VERSION ""

NS_ :

BS_:

BU_: TMS WPM2 WPM1 VCU EHPS_R EHPS_F BrakeSystemController SAS SIM Tester ADCU Cluster CM EBS

BO_ 2566832622 VDHR: 8 Vector__XXX
 SG_ HighResolutionTripDistance : 32|32@1+ (5,0) [0|21055406000] "m" Vector__XXX
 SG_ HghRsolutionTotalVehicleDistance : 0|32@1+ (5,0) [0|21055406000] "m" Vector__XXX

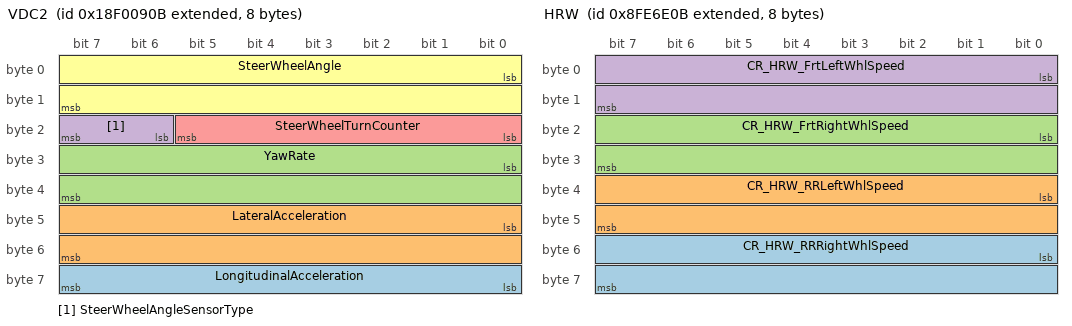
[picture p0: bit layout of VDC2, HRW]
BO_ 2565867787 VDC2: 8 Vector__XXX
 SG_ LongitudinalAcceleration : 56|8@1+ (0.1,-12.5) [-12.5|12.5] "m/s^2" Vector__XXX
 SG_ LateralAcceleration : 40|16@1+ (0.00048828125,-15.687) [-15.687|15.687] "m/s^2" Vector__XXX
 SG_ YawRate : 24|16@1+ (0.0001220703125,-3.92) [-3.92|3.92] "rad/s" Vector__XXX
 SG_ SteerWheelAngleSensorType : 22|2@1+ (1,0) [0|3] "" Vector__XXX
 SG_ SteerWheelTurnCounter : 16|6@1+ (1,-32) [-10|10] "turns" Vector__XXX
 SG_ SteerWheelAngle : 0|16@1+ (0.0009765625,-31.374) [-31.374|31.374] "rad" Vector__XXX

BO_ 2298375691 HRW: 8 BrakeSystemController
 SG_ CR_HRW_RRRightWhlSpeed : 48|16@1+ (0.00390625,0) [0|0] "KPH"  VCU
 SG_ CR_HRW_RRLeftWhlSpeed : 32|16@1+ (0.00390625,0) [0|0] "KPH"  VCU
 SG_ CR_HRW_FrtRightWhlSpeed : 16|16@1+ (0.00390625,0) [0|0] "KPH"  VCU
 SG_ CR_HRW_FrtLeftWhlSpeed : 0|16@1+ (0.00390625,0) [0|0] "KPH"  VCU

BA_DEF_ SG_  "GenSigILSupport" ENUM  "Yes","No";
BA_DEF_ SG_  "GenSigEVName" STRING ;
BA_DEF_ BO_  "GenMsgRequestable" INT 0 1;
BA_DEF_  "NMIdType" INT 0 1;
BA_DEF_ SG_  "SigType" ENUM  "Default","Range","RangeSigned","ASCII","Discrete","Control","ReferencePGN","DTC","StringDelimiter","StringLength","StringLengthControl";
BA_DEF_  "DatabaseVersion" STRING ;
BA_DEF_  "GenNWMApIndRingData" STRING ;
BA_DEF_ SG_  "Purpose" ENUM  "<t.b.d.>","Function","Diagnostic","Development","NM";
BA_DEF_ SG_  "Validity" ENUM  "B+","ACC","IGN";
BA_DEF_ SG_  "SignalCategory" HEX 10 15;
BA_DEF_ SG_  "GenSigStartValue" INT 0 65535;
BA_DEF_ BO_  "VFrameFormat" ENUM  "StandardCAN","ExtendedCAN","reserved","J1939PG";
BA_DEF_ BO_  "RoutingType" ENUM  "<n.a.>","Direct","Indirect";
BA_DEF_ BO_  "GenMsgILSupport" ENUM  "No","Yes";
BA_DEF_ BU_  "ILUsed" ENUM  "No","Yes";
BA_DEF_ BU_  "NmCAN" INT 1 2;
BA_DEF_  "ProtocolType" STRING ;
BA_DEF_  "SyncJumpWidthMax" INT 1 8;
BA_DEF_  "SyncJumpWidthMin" INT 1 4;
BA_DEF_  "SamplePointMax" INT 50 85;
BA_DEF_  "SamplePointMin" INT 55 85;
BA_DEF_  "Baudrate" INT 50000 500000;
BA_DEF_  "Manufacturer" STRING ;
BA_DEF_  "NmMessageCount" INT 0 256;
BA_DEF_  "NmBaseAddress" HEX 0 536870911;
BA_DEF_  "NmType" STRING ;
BA_DEF_  "VersionDay" INT 1 31;
BA_DEF_  "VersionMonth" INT 1 12;
BA_DEF_  "VersionYear" INT 0 9999;
BA_DEF_  "VersionWeek" INT 1 53;
BA_DEF_  "GenNWMTalkNM" STRING ;
BA_DEF_  "GenNWMSleepTime" INT 1375 1650;
BA_DEF_  "GenNWMGotoMode_BusSleep" STRING ;
BA_DEF_  "GenNWMGotoMode_Awake" STRING ;
BA_DEF_  "GenNWMApCanWakeUp" STRING ;
BA_DEF_  "GenNWMApCanSleep" STRING ;
BA_DEF_  "GenNWMApCanOn" STRING ;
BA_DEF_  "GenNWMApCanOff" STRING ;
BA_DEF_  "GenNWMApCanNormal" STRING ;
BA_DEF_  "GenNWMApBusSleep" STRING ;
BA_DEF_ SG_  "GenSigSendType" ENUM  "NotUsed","OnWrite","OnWriteWithRepetition","OnChange","OnChangeWithRepetition","IfActive","IfActiveWithRepetition","NoSigSendType";
BA_DEF_ BO_  "GenMsgCycleTime" INT 0 3600000;
BA_DEF_ BO_  "GenMsgSendType" ENUM  "Cyclic","reserved","cyclicIfActive","reserved","reserved","reserved","reserved","reserved","NoMsgSendType";
BA_DEF_ BU_  "NmStationAddress" INT 0 255;
BA_DEF_  "DBName" STRING ;
BA_DEF_  "BusType" STRING ;
BA_DEF_ BU_  "NodeLayerModules" STRING ;
BA_DEF_REL_ BU_SG_REL_  "GenSigTimeoutTime" INT 0 7000;
BA_DEF_DEF_  "GenSigILSupport" "Yes";
BA_DEF_DEF_  "GenSigEVName" "Env@Nodename_@Signame";
BA_DEF_DEF_  "GenMsgRequestable" 1;
BA_DEF_DEF_  "NMIdType" 1;
BA_DEF_DEF_  "SigType" "Default";
BA_DEF_DEF_  "DatabaseVersion" "";
BA_DEF_DEF_  "GenNWMApIndRingData" "apIndRingData()";
BA_DEF_DEF_  "Purpose" "<t.b.d.>";
BA_DEF_DEF_  "Validity" "IGN";
BA_DEF_DEF_  "SignalCategory" 12;
BA_DEF_DEF_  "GenSigStartValue" 0;
BA_DEF_DEF_  "VFrameFormat" "J1939PG";
BA_DEF_DEF_  "RoutingType" "<n.a.>";
BA_DEF_DEF_  "GenMsgILSupport" "No";
BA_DEF_DEF_  "ILUsed" "Yes";
BA_DEF_DEF_  "NmCAN" 1;
BA_DEF_DEF_  "ProtocolType" "";
BA_DEF_DEF_  "SyncJumpWidthMax" 4;
BA_DEF_DEF_  "SyncJumpWidthMin" 2;
BA_DEF_DEF_  "SamplePointMax" 82;
BA_DEF_DEF_  "SamplePointMin" 75;
BA_DEF_DEF_  "Baudrate" 500000;
BA_DEF_DEF_  "Manufacturer" "HMC";
BA_DEF_DEF_  "NmMessageCount" 256;
BA_DEF_DEF_  "NmBaseAddress" 218038272;
BA_DEF_DEF_  "NmType" "Vector";
BA_DEF_DEF_  "VersionDay" 1;
BA_DEF_DEF_  "VersionMonth" 1;
BA_DEF_DEF_  "VersionYear" 0;
BA_DEF_DEF_  "VersionWeek" 1;
BA_DEF_DEF_  "GenNWMTalkNM" "TalkNM()";
BA_DEF_DEF_  "GenNWMSleepTime" 1500;
BA_DEF_DEF_  "GenNWMGotoMode_BusSleep" "GotoMode_BusSleep()";
BA_DEF_DEF_  "GenNWMGotoMode_Awake" "GotoMode_Awake()";
BA_DEF_DEF_  "GenNWMApCanWakeUp" "apCanWakeUp()";
BA_DEF_DEF_  "GenNWMApCanSleep" "apCanSleep()";
BA_DEF_DEF_  "GenNWMApCanOn" "apCanOn()";
BA_DEF_DEF_  "GenNWMApCanOff" "apCanOff()";
BA_DEF_DEF_  "GenNWMApCanNormal" "apCanNormal()";
BA_DEF_DEF_  "GenNWMApBusSleep" "apBusSleep()";
BA_DEF_DEF_  "GenSigSendType" "NoSigSendType";
BA_DEF_DEF_  "GenMsgCycleTime" 0;
BA_DEF_DEF_  "GenMsgSendType" "NoMsgSendType";
BA_DEF_DEF_  "NmStationAddress" 254;
BA_DEF_DEF_  "DBName" "";
BA_DEF_DEF_  "BusType" "";
BA_DEF_DEF_  "NodeLayerModules" "CANoeILNLVector.dll";
BA_DEF_DEF_REL_ "GenSigTimeoutTime" 500;
BA_ "BusType" "CAN";
BA_ "DatabaseVersion" "14.06.01";
BA_ "ProtocolType" "J1939";
BA_ "VersionDay" 2;
BA_ "VersionMonth" 6;
BA_ "VersionYear" 2014;
BA_ "VersionWeek" 22;
BA_ "DBName" "CCAN";
BA_ "NmStationAddress" BU_ TMS 25;
BA_ "NmStationAddress" BU_ WPM2 58;
BA_ "NmStationAddress" BU_ WPM1 57;
BA_ "NmStationAddress" BU_ VCU 239;
BA_ "NmStationAddress" BU_ EHPS_R 71;
BA_ "NmStationAddress" BU_ EHPS_F 19;
BA_ "NmStationAddress" BU_ BrakeSystemController 11;
BA_ "NmStationAddress" BU_ SAS 228;
BA_ "NmStationAddress" BU_ SIM 0;
BA_ "NmStationAddress" BU_ Tester 249;
BA_ "NmStationAddress" BU_ ADCU 42;
BA_ "GenMsgCycleTime" BO_ 2566832622 1000;
BA_ "GenMsgSendType" BO_ 2566832622 0;
BA_ "GenMsgCycleTime" BO_ 2565867787 10;
BA_ "GenMsgSendType" BO_ 2565867787 0;
BA_ "GenMsgSendType" BO_ 2298375691 0;
BA_ "GenMsgCycleTime" BO_ 2298375691 20;
BA_ "GenMsgILSupport" BO_ 2298375691 1;
BA_ "GenSigStartValue" SG_ 2565867787 SteerWheelTurnCounter 22;
